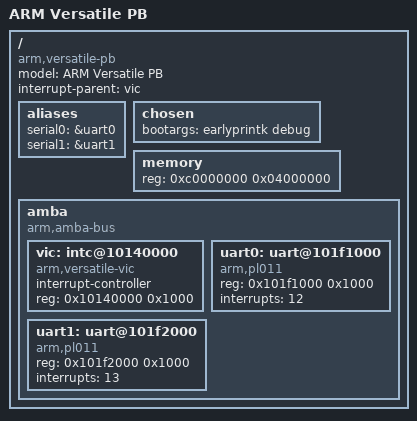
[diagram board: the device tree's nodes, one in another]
/dts-v1/;

/ {
	#address-cells = <1>;
	#size-cells = <1>;
	model = "ARM Versatile PB";
	compatible = "arm,versatile-pb";
	interrupt-parent = <&vic>;
	
	aliases {
		serial0 = &uart0;
		serial1 = &uart1;
	};
	
	chosen {
		bootargs = "earlyprintk debug";
	};
	
	memory {
		device_type = "memory";
		reg = <0xc0000000 0x04000000>;
	};
	
	amba {
		compatible = "arm,amba-bus";
		#address-cells = <1>;
		#size-cells = <1>;
		ranges;
		
		vic: intc@10140000 {
			compatible = "arm,versatile-vic";
			interrupt-controller;
			#interrupt-cells = <1>;
			reg = <0x10140000 0x1000>;
		};

		uart0: uart@101f1000 {
			compatible = "arm,pl011", "arm,primecell";
			reg = <0x101f1000 0x1000>;
			interrupts = <12>;
		};

		uart1: uart@101f2000 {
			compatible = "arm,pl011", "arm,primecell";
			reg = <0x101f2000 0x1000>;
			interrupts = <13>;
		};
	};
};
